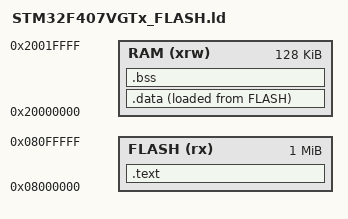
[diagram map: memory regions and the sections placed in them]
ENTRY(Reset_Handler)

MEMORY
{
    FLASH (rx)  : ORIGIN = 0x08000000, LENGTH = 1024K
    RAM   (xrw) : ORIGIN = 0x20000000, LENGTH = 128K
}

/* Stack top */
_estack = ORIGIN(RAM) + LENGTH(RAM);

SECTIONS
{
    .text :
    {
        KEEP(*(.isr_vector))
        *(.text*)
        *(.rodata*)
        _etext = .;
    } > FLASH

    _sidata = LOADADDR(.data);

    .data : 
    {
        _sdata = .;
        *(.data*)
        _edata = .;
    } > RAM AT > FLASH

    .bss :
    {
        _sbss = .;
        *(.bss*)
        *(COMMON)
        _ebss = .;
    } > RAM
}
